# CC26x0 register map
File version: 2.3
CPU: CM3 r2p1, little endian, no MPU, no FPU, 0x3 interrupt priority bits, 0x0 interrupts
Registers are 32-bit, read-write, reset 0x0 unless marked. A register's access mark holds for its fields unless they carry their own. Offsets are from the block's base; [hi:lo] are bit positions; {n}, {i} and the like mark numbered series.

## AUX_ADI4 — Configuration registers controlling analog peripherals of AUX. Registers Fields should be considered static unless otherwise noted (as dynamic)
Base 0x400CB000
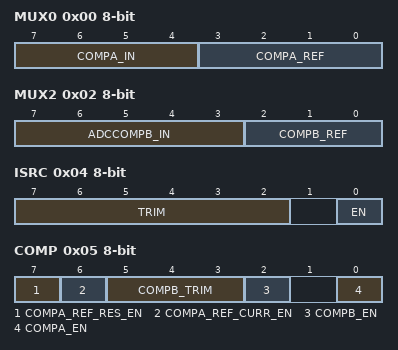
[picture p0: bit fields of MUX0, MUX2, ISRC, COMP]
0x00 MUX0 8-bit — Internal. Only to be used through TI provided API.
  [7:4] COMPA_IN, [3:0] COMPA_REF
0x01 MUX1 8-bit — Internal. Only to be used through TI provided API.
  [7:0] COMPA_IN
0x02 MUX2 8-bit — Internal. Only to be used through TI provided API.
  [7:3] ADCCOMPB_IN, [2:0] COMPB_REF
0x03 MUX3 8-bit — Internal. Only to be used through TI provided API.
  [7:0] ADCCOMPB_IN
0x04 ISRC 8-bit — Current Source Strength and trim control for current source
  [7:2] TRIM, [0] EN
0x05 COMP 8-bit — Comparator Control COMPA and COMPB comparators
  [7] COMPA_REF_RES_EN, [6] COMPA_REF_CURR_EN, [5:3] COMPB_TRIM, [2] COMPB_EN, [0] COMPA_EN
0x07 MUX4 8-bit — Internal. Only to be used through TI provided API.
  [7:0] COMPA_REF
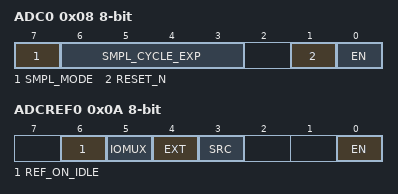
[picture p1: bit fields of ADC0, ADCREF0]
0x08 ADC0 8-bit — ADC Control 0
  [7] SMPL_MODE, [6:3] SMPL_CYCLE_EXP, [1] RESET_N, [0] EN
0x09 ADC1 8-bit — ADC Control 1
  [0] SCALE_DIS
0x0A ADCREF0 8-bit — ADC Reference 0 Control reference used by the ADC
  [6] REF_ON_IDLE, [5] IOMUX, [4] EXT, [3] SRC, [0] EN
0x0B ADCREF1 8-bit — ADC Reference 1 Control reference used by the ADC
  [5:0] VTRIM

## AUX_AIODIO0 — AUX Analog/Digital Input Output Controller
Base 0x400C1000
Same registers: AUX_AIODIO1 0x400C2000
0x00 GPIODOUT — General Purpose Input/Output Data Out This register is used to set data on the pads assigned to AUX
  [7:0] IO7_0
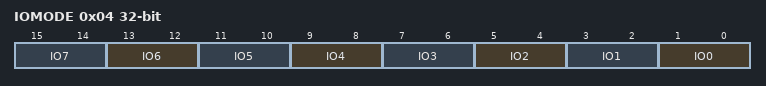
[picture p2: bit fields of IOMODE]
0x04 IOMODE — Input Output Mode Controls pull-up pull-down and output mode for the IO pins assigned to AUX
  [2n+1:2n] IO{n} (n=0..7)
0x08 GPIODIN ro — General Purpose Input Output Data In
  [7:0] IO7_0
0x0C GPIODOUTSET — General Purpose Input Output Data Out Set Strobes for setting output data register bits
  [7:0] IO7_0
0x10 GPIODOUTCLR — General Purpose Input Output Data Out Clear Strobes for clearing output data register bits
  [7:0] IO7_0
0x14 GPIODOUTTGL — General Purpose Input Output Data Out Toggle Strobes for toggling output data register bits
  [7:0] IO7_0
0x18 GPIODIE — General Purpose Input Output Input Enable
  [7:0] IO7_0

## AUX_ANAIF — AUX Analog Peripheral Control Module
Base 0x400C9000
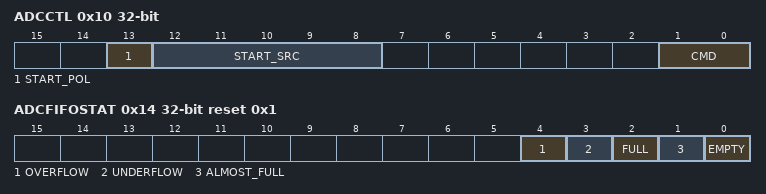
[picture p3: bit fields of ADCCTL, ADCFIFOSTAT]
0x10 ADCCTL — ADC Control
  [13] START_POL, [12:8] START_SRC, [1:0] CMD
0x14 ADCFIFOSTAT ro reset 0x1 — ADC FIFO Status FIFO can hold up to four ADC samples
  [4] OVERFLOW, [3] UNDERFLOW, [2] FULL, [1] ALMOST_FULL, [0] EMPTY
0x18 ADCFIFO
  [11:0] DATA
0x1C ADCTRIG — ADC Trigger
  [0] START
0x20 ISRCCTL reset 0x1 — Current Source Control
  [0] RESET_N

## AUX_DDI0_OSC — This is the DDI for the digital block that controls all the analog clock oscillators (OSC_DIG) and performs qualification of the clocks generated.
Base 0x400CA000
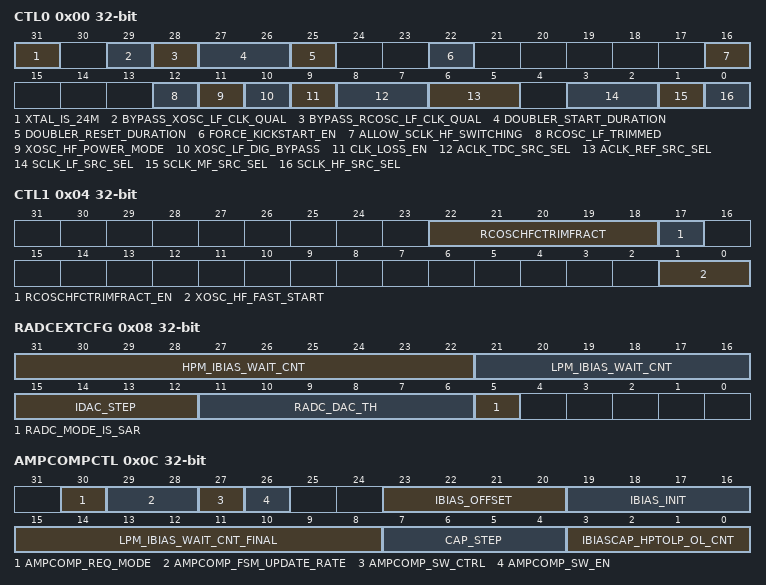
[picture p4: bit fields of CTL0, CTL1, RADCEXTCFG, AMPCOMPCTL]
0x00 CTL0 — Control 0 Controls various clock source selects
  [31] XTAL_IS_24M, [29] BYPASS_XOSC_LF_CLK_QUAL, [28] BYPASS_RCOSC_LF_CLK_QUAL, [27:26] DOUBLER_START_DURATION, [25] DOUBLER_RESET_DURATION, [22] FORCE_KICKSTART_EN, [16] ALLOW_SCLK_HF_SWITCHING, [12] RCOSC_LF_TRIMMED, [11] XOSC_HF_POWER_MODE, [10] XOSC_LF_DIG_BYPASS, [9] CLK_LOSS_EN, [8:7] ACLK_TDC_SRC_SEL, [6:5] ACLK_REF_SRC_SEL, [3:2] SCLK_LF_SRC_SEL, [1] SCLK_MF_SRC_SEL, [0] SCLK_HF_SRC_SEL
0x04 CTL1 — Control 1 This register contains various OSC_DIG configuration
  [22:18] RCOSCHFCTRIMFRACT, [17] RCOSCHFCTRIMFRACT_EN, [1:0] XOSC_HF_FAST_START
0x08 RADCEXTCFG — RADC External Configuration
  [31:22] HPM_IBIAS_WAIT_CNT, [21:16] LPM_IBIAS_WAIT_CNT, [15:12] IDAC_STEP, [11:6] RADC_DAC_TH, [5] RADC_MODE_IS_SAR
0x0C AMPCOMPCTL — Amplitude Compensation Control
  [30] AMPCOMP_REQ_MODE, [29:28] AMPCOMP_FSM_UPDATE_RATE, [27] AMPCOMP_SW_CTRL, [26] AMPCOMP_SW_EN, [23:20] IBIAS_OFFSET, [19:16] IBIAS_INIT, [15:8] LPM_IBIAS_WAIT_CNT_FINAL, [7:4] CAP_STEP, [3:0] IBIASCAP_HPTOLP_OL_CNT
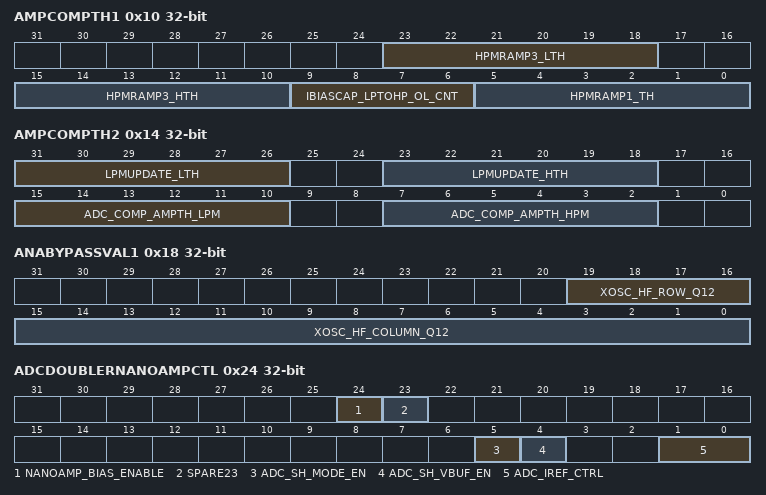
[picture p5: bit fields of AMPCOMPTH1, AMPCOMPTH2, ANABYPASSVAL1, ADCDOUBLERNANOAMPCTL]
0x10 AMPCOMPTH1 — Amplitude Compensation Threashold 1 This register contains various threshhold values for amplitude compensation algorithm
  [23:18] HPMRAMP3_LTH, [15:10] HPMRAMP3_HTH, [9:6] IBIASCAP_LPTOHP_OL_CNT, [5:0] HPMRAMP1_TH
0x14 AMPCOMPTH2 — Amplitude Compensation Threashold 2 This register contains various threshhold values for amplitude compensation algorithm.
  [31:26] LPMUPDATE_LTH, [23:18] LPMUPDATE_HTH, [15:10] ADC_COMP_AMPTH_LPM, [7:2] ADC_COMP_AMPTH_HPM
0x18 ANABYPASSVAL1 — Analog Bypass Values 1
  [19:16] XOSC_HF_ROW_Q12, [15:0] XOSC_HF_COLUMN_Q12
0x1C ANABYPASSVAL2 — Internal. Only to be used through TI provided API.
  [13:0] XOSC_HF_IBIASTHERM
0x20 ATESTCTL — Analog Test Control
  [29] SCLK_LF_AUX_EN
0x24 ADCDOUBLERNANOAMPCTL — ADC Doubler Nanoamp Control
  [24] NANOAMP_BIAS_ENABLE, [23] SPARE23, [5] ADC_SH_MODE_EN, [4] ADC_SH_VBUF_EN, [1:0] ADC_IREF_CTRL
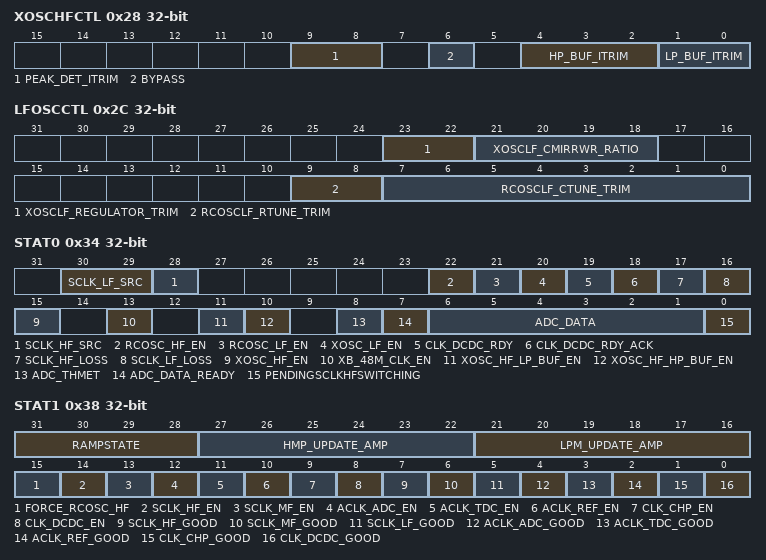
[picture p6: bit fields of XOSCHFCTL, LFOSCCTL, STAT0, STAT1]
0x28 XOSCHFCTL — XOSCHF Control
  [9:8] PEAK_DET_ITRIM, [6] BYPASS, [4:2] HP_BUF_ITRIM, [1:0] LP_BUF_ITRIM
0x2C LFOSCCTL — Low Frequency Oscillator Control
  [23:22] XOSCLF_REGULATOR_TRIM, [21:18] XOSCLF_CMIRRWR_RATIO, [9:8] RCOSCLF_RTUNE_TRIM, [7:0] RCOSCLF_CTUNE_TRIM
0x30 RCOSCHFCTL — RCOSCHF Control
  [15:8] RCOSCHF_CTRIM
0x34 STAT0 ro — Status 0 This register contains status signals from OSC_DIG
  [30:29] SCLK_LF_SRC, [28] SCLK_HF_SRC, [22] RCOSC_HF_EN, [21] RCOSC_LF_EN, [20] XOSC_LF_EN, [19] CLK_DCDC_RDY, [18] CLK_DCDC_RDY_ACK, [17] SCLK_HF_LOSS, [16] SCLK_LF_LOSS, [15] XOSC_HF_EN, [13] XB_48M_CLK_EN, [11] XOSC_HF_LP_BUF_EN, [10] XOSC_HF_HP_BUF_EN, [8] ADC_THMET, [7] ADC_DATA_READY, [6:1] ADC_DATA, [0] PENDINGSCLKHFSWITCHING
0x38 STAT1 ro — Status 1 This register contains status signals from OSC_DIG
  [31:28] RAMPSTATE, [27:22] HMP_UPDATE_AMP, [21:16] LPM_UPDATE_AMP, [15] FORCE_RCOSC_HF, [14] SCLK_HF_EN, [13] SCLK_MF_EN, [12] ACLK_ADC_EN, [11] ACLK_TDC_EN, [10] ACLK_REF_EN, [9] CLK_CHP_EN, [8] CLK_DCDC_EN, [7] SCLK_HF_GOOD, [6] SCLK_MF_GOOD, [5] SCLK_LF_GOOD, [4] ACLK_ADC_GOOD, [3] ACLK_TDC_GOOD, [2] ACLK_REF_GOOD, [1] CLK_CHP_GOOD, [0] CLK_DCDC_GOOD
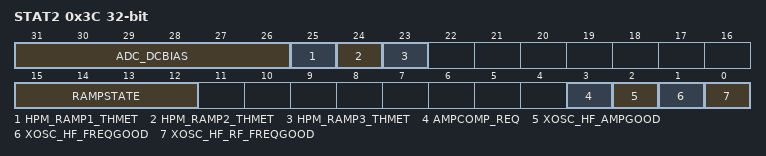
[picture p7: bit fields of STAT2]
0x3C STAT2 ro — Status 2 This register contains status signals from AMPCOMP FSM
  [31:26] ADC_DCBIAS, [25] HPM_RAMP1_THMET, [24] HPM_RAMP2_THMET, [23] HPM_RAMP3_THMET, [15:12] RAMPSTATE, [3] AMPCOMP_REQ, [2] XOSC_HF_AMPGOOD, [1] XOSC_HF_FREQGOOD, [0] XOSC_HF_RF_FREQGOOD
